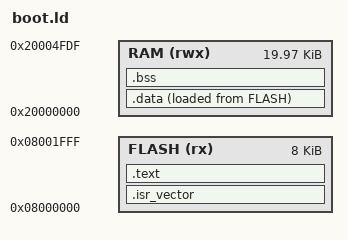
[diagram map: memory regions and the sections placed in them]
ENTRY(Reset_Handler)
MEMORY {
 FLASH (rx) : ORIGIN = 0x08000000, LENGTH = 8K
 RAM (rwx) : ORIGIN = 0x20000000, LENGTH = 20K-32
}
SECTIONS {
 .isr_vector : { KEEP(*(.isr_vector)) } >FLASH
 .text : { *(.text*) *(.rodata*) . = ALIGN(4); } >FLASH
 .data : { . = ALIGN(4); _sdata = .; *(.data*) . = ALIGN(4); _edata = .; } >RAM AT>FLASH
 _sidata = LOADADDR(.data);
 .bss (NOLOAD) : { . = ALIGN(4); _sbss = .; *(.bss*) *(COMMON) . = ALIGN(4); _ebss = .; } >RAM
 /DISCARD/ : { *(.comment*) *(.ARM.exidx*) *(.ARM.extab*) *(.eh_frame*) }
}
ASSERT(_ebss + 2048 <= ORIGIN(RAM)+LENGTH(RAM), "Boot stack margin below 2 KiB")
